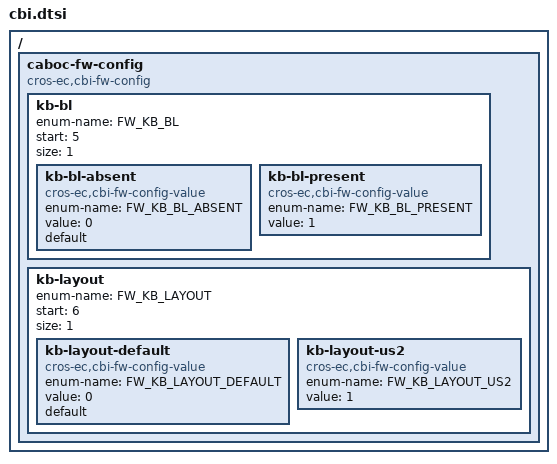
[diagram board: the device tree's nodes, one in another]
/* Copyright 2025 The ChromiumOS Authors
 * Use of this source code is governed by a BSD-style license that can be
 * found in the LICENSE file.
 */

/ {
	caboc-fw-config {
		compatible = "cros-ec,cbi-fw-config";

		/*
		 * FW_CONFIG field to enable KB back light or not.
		 */
		kb-bl {
			enum-name = "FW_KB_BL";
			start = <5>;
			size = <1>;

			kb-bl-absent {
				compatible = "cros-ec,cbi-fw-config-value";
				enum-name = "FW_KB_BL_ABSENT";
				value = <0>;
				default;
			};
			kb-bl-present {
				compatible = "cros-ec,cbi-fw-config-value";
				enum-name = "FW_KB_BL_PRESENT";
				value = <1>;
			};
		};

		/*
		 * FW_CONFIG field to decide default or US2 KB layout.
		 */
		 kb-layout {
			enum-name = "FW_KB_LAYOUT";
			start = <6>;
			size = <1>;

			kb-layout-default {
				compatible = "cros-ec,cbi-fw-config-value";
				enum-name = "FW_KB_LAYOUT_DEFAULT";
				value = <0>;
				default;
			};
			kb-layout-us2 {
				compatible = "cros-ec,cbi-fw-config-value";
				enum-name = "FW_KB_LAYOUT_US2";
				value = <1>;
			};
		};
	};
};
